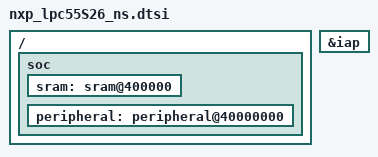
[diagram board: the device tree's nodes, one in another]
/*
 * Copyright (c) 2024 Maxime Vincent <maxime@veemax.be>
 *
 * SPDX-License-Identifier: Apache-2.0
 */

/ {
	soc {
		sram: sram@400000 {
			ranges = <0x4000000 0x4000000 0x20000000>;
		};

		peripheral: peripheral@40000000 {
			ranges = <0x0 0x40000000 0x10000000>;
		};
	};
};

#include "nxp_lpc55S2x_common.dtsi"

&iap {
	status = "okay";
};
